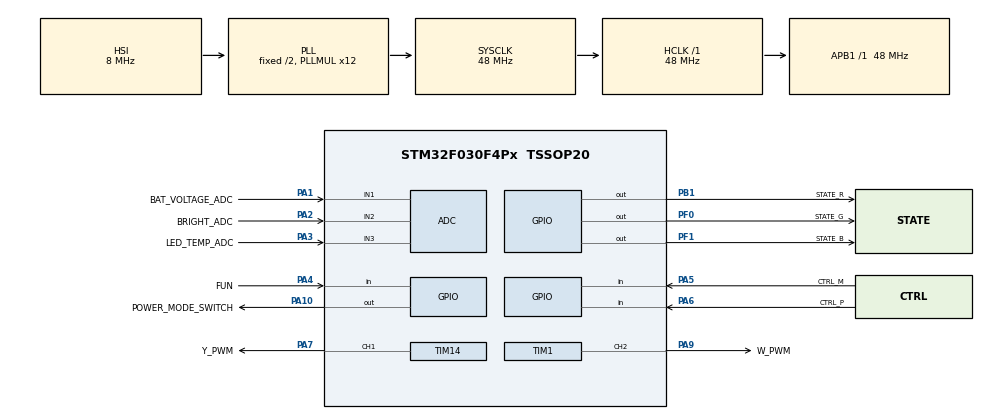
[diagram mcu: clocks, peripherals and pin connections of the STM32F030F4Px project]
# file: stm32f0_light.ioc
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ADC.SamplingTime=ADC_SAMPLETIME_239CYCLES_5
Mcu.Family=STM32F0
Mcu.Name=STM32F030F4Px
Mcu.Package=TSSOP20
PA0.GPIO_Label=SYS_WKUP
PA0.Mode=SYS_WakeUp0
PA0.Signal=SYS_WKUP1
PA1.GPIO_Label=BAT_VOLTAGE_ADC
PA1.Mode=IN1
PA1.Signal=ADC_IN1
PA10.GPIO_Label=POWER_MODE_SWITCH
PA10.Signal=GPIO_Output
PA13.Mode=Serial_Wire
PA13.Signal=SYS_SWDIO
PA14.Mode=Serial_Wire
PA14.Signal=SYS_SWCLK
PA2.GPIO_Label=BRIGHT_ADC
PA2.Mode=IN2
PA2.Signal=ADC_IN2
PA3.GPIO_Label=LED_TEMP_ADC
PA3.Mode=IN3
PA3.Signal=ADC_IN3
PA4.GPIO_Label=FUN
PA4.Signal=GPIO_Input
PA5.GPIO_Label=CTRL_M
PA5.Signal=GPIO_Input
PA6.GPIO_Label=CTRL_P
PA6.Signal=GPIO_Input
PA7.GPIO_Label=Y_PWM
PA7.Signal=S_TIM14_CH1
PA9.GPIO_Label=W_PWM
PA9.Signal=S_TIM1_CH2
PB1.GPIO_Label=STATE_R
PB1.PinState=GPIO_PIN_SET
PB1.Signal=GPIO_Output
PF0-OSC_IN.GPIO_Label=STATE_G
PF0-OSC_IN.PinState=GPIO_PIN_SET
PF0-OSC_IN.Signal=GPIO_Output
PF1-OSC_OUT.GPIO_Label=STATE_B
PF1-OSC_OUT.PinState=GPIO_PIN_SET
PF1-OSC_OUT.Signal=GPIO_Output
ProjectManager.HeapSize=0x200
ProjectManager.StackSize=0x400
ProjectManager.TargetToolchain=CMake
RCC.AHBFreq_Value=48000000
RCC.APB1Freq_Value=48000000
RCC.APB1TimFreq_Value=48000000
RCC.HCLKFreq_Value=48000000
RCC.PLLMUL=RCC_PLL_MUL12
RCC.SYSCLKFreq_VALUE=48000000
RCC.SYSCLKSource=RCC_SYSCLKSOURCE_PLLCLK
SH.S_TIM14_CH1.0=TIM14_CH1,PWM Generation1 CH1
SH.S_TIM1_CH2.0=TIM1_CH2,PWM Generation2 CH2
TIM1.AutoReloadPreload=TIM_AUTORELOAD_PRELOAD_ENABLE
TIM1.Channel-PWM\ Generation2\ CH2=TIM_CHANNEL_2
TIM1.Period=4799
TIM14.AutoReloadPreload=TIM_AUTORELOAD_PRELOAD_ENABLE
TIM14.Channel=TIM_CHANNEL_1
TIM14.Period=4799
TIM14.Pulse=0
VP_TIM14_VS_ClockSourceINT.Mode=Enable_Timer
VP_TIM1_VS_ClockSourceINT.Mode=Internal
board=custom

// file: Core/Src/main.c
/* USER CODE BEGIN Header */
/**
  ******************************************************************************
  * @file           : main.c
  * @brief          : Main program body
  ******************************************************************************
  * @attention
  *
  * Copyright (c) 2026 STMicroelectronics.
  * All rights reserved.
  *
  * This software is licensed under terms that can be found in the LICENSE file
  * in the root directory of this software component.
  * If no LICENSE file comes with this software, it is provided AS-IS.
  *
  ******************************************************************************
  */
/* USER CODE END Header */
#include "main.h"

#include "app.h"

ADC_HandleTypeDef hadc;

TIM_HandleTypeDef htim1;
TIM_HandleTypeDef htim14;

void SystemClock_Config(void);
static void MX_GPIO_Init(void);
static void MX_ADC_Init(void);
static void MX_TIM1_Init(void);
static void MX_TIM14_Init(void);

int main(void)
{

  /* MCU Configuration--------------------------------------------------------*/

  /* Reset of all peripherals, Initializes the Flash interface and the Systick. */
  HAL_Init();

  /* Configure the system clock */
  SystemClock_Config();

  /* Initialize all configured peripherals */
  MX_GPIO_Init();
  MX_ADC_Init();
  MX_TIM1_Init();
  MX_TIM14_Init();
  /* USER CODE BEGIN 2 */
  App_Setup();
  /* USER CODE END 2 */

  /* Infinite loop */
  /* USER CODE BEGIN WHILE */
  while (1)
  {
    App_Loop();
    /* USER CODE END WHILE */

  }
}

void SystemClock_Config(void)
{
  RCC_OscInitTypeDef RCC_OscInitStruct = {0};
  RCC_ClkInitTypeDef RCC_ClkInitStruct = {0};

  /** Initializes the RCC Oscillators according to the specified parameters
  * in the RCC_OscInitTypeDef structure.
  */
  RCC_OscInitStruct.OscillatorType = RCC_OSCILLATORTYPE_HSI|RCC_OSCILLATORTYPE_HSI14;
  RCC_OscInitStruct.HSIState = RCC_HSI_ON;
  RCC_OscInitStruct.HSI14State = RCC_HSI14_ON;
  RCC_OscInitStruct.HSICalibrationValue = RCC_HSICALIBRATION_DEFAULT;
  RCC_OscInitStruct.HSI14CalibrationValue = 16;
  RCC_OscInitStruct.PLL.PLLState = RCC_PLL_ON;
  RCC_OscInitStruct.PLL.PLLSource = RCC_PLLSOURCE_HSI;
  RCC_OscInitStruct.PLL.PLLMUL = RCC_PLL_MUL12;
  RCC_OscInitStruct.PLL.PREDIV = RCC_PREDIV_DIV1;
  if (HAL_RCC_OscConfig(&RCC_OscInitStruct) != HAL_OK)
  {
    Error_Handler();
  }

  /** Initializes the CPU, AHB and APB buses clocks
  */
  RCC_ClkInitStruct.ClockType = RCC_CLOCKTYPE_HCLK|RCC_CLOCKTYPE_SYSCLK
                              |RCC_CLOCKTYPE_PCLK1;
  RCC_ClkInitStruct.SYSCLKSource = RCC_SYSCLKSOURCE_PLLCLK;
  RCC_ClkInitStruct.AHBCLKDivider = RCC_SYSCLK_DIV1;
  RCC_ClkInitStruct.APB1CLKDivider = RCC_HCLK_DIV1;

  if (HAL_RCC_ClockConfig(&RCC_ClkInitStruct, FLASH_LATENCY_1) != HAL_OK)
  {
    Error_Handler();
  }
}

static void MX_ADC_Init(void)
{

  ADC_ChannelConfTypeDef sConfig = {0};

  /** Configure the global features of the ADC (Clock, Resolution, Data Alignment and number of conversion)
  */
  hadc.Instance = ADC1;
  hadc.Init.ClockPrescaler = ADC_CLOCK_ASYNC_DIV1;
  hadc.Init.Resolution = ADC_RESOLUTION_12B;
  hadc.Init.DataAlign = ADC_DATAALIGN_RIGHT;
  hadc.Init.ScanConvMode = ADC_SCAN_DIRECTION_FORWARD;
  hadc.Init.EOCSelection = ADC_EOC_SINGLE_CONV;
  hadc.Init.LowPowerAutoWait = DISABLE;
  hadc.Init.LowPowerAutoPowerOff = DISABLE;
  hadc.Init.ContinuousConvMode = DISABLE;
  hadc.Init.DiscontinuousConvMode = DISABLE;
  hadc.Init.ExternalTrigConv = ADC_SOFTWARE_START;
  hadc.Init.ExternalTrigConvEdge = ADC_EXTERNALTRIGCONVEDGE_NONE;
  hadc.Init.DMAContinuousRequests = DISABLE;
  hadc.Init.Overrun = ADC_OVR_DATA_PRESERVED;
  if (HAL_ADC_Init(&hadc) != HAL_OK)
  {
    Error_Handler();
  }

  /** Configure for the selected ADC regular channel to be converted.
  */
  sConfig.Channel = ADC_CHANNEL_1;
  sConfig.Rank = ADC_RANK_CHANNEL_NUMBER;
  sConfig.SamplingTime = ADC_SAMPLETIME_239CYCLES_5;
  if (HAL_ADC_ConfigChannel(&hadc, &sConfig) != HAL_OK)
  {
    Error_Handler();
  }

  /** Configure for the selected ADC regular channel to be converted.
  */
  sConfig.Channel = ADC_CHANNEL_2;
  if (HAL_ADC_ConfigChannel(&hadc, &sConfig) != HAL_OK)
  {
    Error_Handler();
  }

  /** Configure for the selected ADC regular channel to be converted.
  */
  sConfig.Channel = ADC_CHANNEL_3;
  if (HAL_ADC_ConfigChannel(&hadc, &sConfig) != HAL_OK)
  {
    Error_Handler();
  }

}

static void MX_TIM1_Init(void)
{

  TIM_ClockConfigTypeDef sClockSourceConfig = {0};
  TIM_MasterConfigTypeDef sMasterConfig = {0};
  TIM_OC_InitTypeDef sConfigOC = {0};
  TIM_BreakDeadTimeConfigTypeDef sBreakDeadTimeConfig = {0};

  htim1.Instance = TIM1;
  htim1.Init.Prescaler = 0;
  htim1.Init.CounterMode = TIM_COUNTERMODE_UP;
  htim1.Init.Period = 4799;
  htim1.Init.ClockDivision = TIM_CLOCKDIVISION_DIV1;
  htim1.Init.RepetitionCounter = 0;
  htim1.Init.AutoReloadPreload = TIM_AUTORELOAD_PRELOAD_ENABLE;
  if (HAL_TIM_Base_Init(&htim1) != HAL_OK)
  {
    Error_Handler();
  }
  sClockSourceConfig.ClockSource = TIM_CLOCKSOURCE_INTERNAL;
  if (HAL_TIM_ConfigClockSource(&htim1, &sClockSourceConfig) != HAL_OK)
  {
    Error_Handler();
  }
  if (HAL_TIM_PWM_Init(&htim1) != HAL_OK)
  {
    Error_Handler();
  }
  sMasterConfig.MasterOutputTrigger = TIM_TRGO_RESET;
  sMasterConfig.MasterSlaveMode = TIM_MASTERSLAVEMODE_DISABLE;
  if (HAL_TIMEx_MasterConfigSynchronization(&htim1, &sMasterConfig) != HAL_OK)
  {
    Error_Handler();
  }
  sConfigOC.OCMode = TIM_OCMODE_PWM1;
  sConfigOC.Pulse = 0;
  sConfigOC.OCPolarity = TIM_OCPOLARITY_HIGH;
  sConfigOC.OCNPolarity = TIM_OCNPOLARITY_HIGH;
  sConfigOC.OCFastMode = TIM_OCFAST_DISABLE;
  sConfigOC.OCIdleState = TIM_OCIDLESTATE_RESET;
  sConfigOC.OCNIdleState = TIM_OCNIDLESTATE_RESET;
  if (HAL_TIM_PWM_ConfigChannel(&htim1, &sConfigOC, TIM_CHANNEL_2) != HAL_OK)
  {
    Error_Handler();
  }
  sBreakDeadTimeConfig.OffStateRunMode = TIM_OSSR_DISABLE;
  sBreakDeadTimeConfig.OffStateIDLEMode = TIM_OSSI_DISABLE;
  sBreakDeadTimeConfig.LockLevel = TIM_LOCKLEVEL_OFF;
  sBreakDeadTimeConfig.DeadTime = 0;
  sBreakDeadTimeConfig.BreakState = TIM_BREAK_DISABLE;
  sBreakDeadTimeConfig.BreakPolarity = TIM_BREAKPOLARITY_HIGH;
  sBreakDeadTimeConfig.AutomaticOutput = TIM_AUTOMATICOUTPUT_DISABLE;
  if (HAL_TIMEx_ConfigBreakDeadTime(&htim1, &sBreakDeadTimeConfig) != HAL_OK)
  {
    Error_Handler();
  }
  HAL_TIM_MspPostInit(&htim1);

}

static void MX_TIM14_Init(void)
{

  TIM_OC_InitTypeDef sConfigOC = {0};

  htim14.Instance = TIM14;
  htim14.Init.Prescaler = 0;
  htim14.Init.CounterMode = TIM_COUNTERMODE_UP;
  htim14.Init.Period = 4799;
  htim14.Init.ClockDivision = TIM_CLOCKDIVISION_DIV1;
  htim14.Init.AutoReloadPreload = TIM_AUTORELOAD_PRELOAD_ENABLE;
  if (HAL_TIM_Base_Init(&htim14) != HAL_OK)
  {
    Error_Handler();
  }
  if (HAL_TIM_PWM_Init(&htim14) != HAL_OK)
  {
    Error_Handler();
  }
  sConfigOC.OCMode = TIM_OCMODE_PWM1;
  sConfigOC.Pulse = 0;
  sConfigOC.OCPolarity = TIM_OCPOLARITY_HIGH;
  sConfigOC.OCFastMode = TIM_OCFAST_DISABLE;
  if (HAL_TIM_PWM_ConfigChannel(&htim14, &sConfigOC, TIM_CHANNEL_1) != HAL_OK)
  {
    Error_Handler();
  }
  HAL_TIM_MspPostInit(&htim14);

}

static void MX_GPIO_Init(void)
{
  GPIO_InitTypeDef GPIO_InitStruct = {0};

  /* GPIO Ports Clock Enable */
  __HAL_RCC_GPIOF_CLK_ENABLE();
  __HAL_RCC_GPIOA_CLK_ENABLE();
  __HAL_RCC_GPIOB_CLK_ENABLE();

  /*Configure GPIO pin Output Level */
  HAL_GPIO_WritePin(GPIOF, STATE_G_Pin|STATE_B_Pin, GPIO_PIN_SET);

  /*Configure GPIO pin Output Level */
  HAL_GPIO_WritePin(STATE_R_GPIO_Port, STATE_R_Pin, GPIO_PIN_SET);

  /*Configure GPIO pin Output Level */
  HAL_GPIO_WritePin(POWER_MODE_SWITCH_GPIO_Port, POWER_MODE_SWITCH_Pin, GPIO_PIN_RESET);

  GPIO_InitStruct.Pin   = GPIO_PIN_0;
  GPIO_InitStruct.Mode  = GPIO_MODE_INPUT;
  GPIO_InitStruct.Pull  = GPIO_PULLDOWN;
  GPIO_InitStruct.Speed = GPIO_SPEED_FREQ_LOW;
  HAL_GPIO_Init(GPIOA, &GPIO_InitStruct);

  /*Configure GPIO pins : STATE_G_Pin STATE_B_Pin */
  GPIO_InitStruct.Pin = STATE_G_Pin|STATE_B_Pin;
  GPIO_InitStruct.Mode = GPIO_MODE_OUTPUT_PP;
  GPIO_InitStruct.Pull = GPIO_NOPULL;
  GPIO_InitStruct.Speed = GPIO_SPEED_FREQ_LOW;
  HAL_GPIO_Init(GPIOF, &GPIO_InitStruct);

  /*Configure GPIO pins : FUN_Pin CTRL_M_Pin CTRL_P_Pin */
  GPIO_InitStruct.Pin = FUN_Pin|CTRL_M_Pin|CTRL_P_Pin;
  GPIO_InitStruct.Mode = GPIO_MODE_INPUT;
  GPIO_InitStruct.Pull = GPIO_NOPULL;
  HAL_GPIO_Init(GPIOA, &GPIO_InitStruct);

  /*Configure GPIO pin : STATE_R_Pin */
  GPIO_InitStruct.Pin = STATE_R_Pin;
  GPIO_InitStruct.Mode = GPIO_MODE_OUTPUT_PP;
  GPIO_InitStruct.Pull = GPIO_NOPULL;
  GPIO_InitStruct.Speed = GPIO_SPEED_FREQ_LOW;
  HAL_GPIO_Init(STATE_R_GPIO_Port, &GPIO_InitStruct);

  /*Configure GPIO pin : POWER_MODE_SWITCH_Pin */
  GPIO_InitStruct.Pin = POWER_MODE_SWITCH_Pin;
  GPIO_InitStruct.Mode = GPIO_MODE_OUTPUT_PP;
  GPIO_InitStruct.Pull = GPIO_NOPULL;
  GPIO_InitStruct.Speed = GPIO_SPEED_FREQ_LOW;
  HAL_GPIO_Init(POWER_MODE_SWITCH_GPIO_Port, &GPIO_InitStruct);

}

void Error_Handler(void)
{
  __disable_irq();
  while (1)
  {
  }
}
